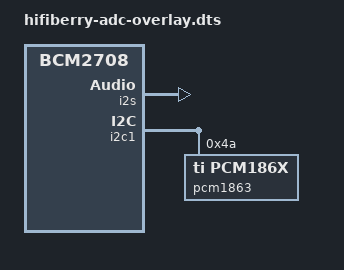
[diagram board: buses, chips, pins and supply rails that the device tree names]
// Definitions for HiFiBerry Digi
/dts-v1/;
/plugin/;

/ {
	compatible = "brcm,bcm2708";

	fragment@0 {
		target = <&sound>;
		__overlay__ {
			compatible = "hifiberry,hifiberry-adc";
			i2s-controller = <&i2s>;
			status = "okay";
		};
	};

	fragment@1 {
		target = <&i2s>;
		__overlay__ {
			status = "okay";
		};
	};

	fragment@2 {
		target = <&i2c1>;
		__overlay__ {
			#address-cells = <1>;
			#size-cells = <0>;
			status = "okay";

			pcm1863@4a {
				#sound-dai-cells = <0>;
				compatible = "ti,pcm186x";
				reg = <0x4a>;
				status = "okay";
			};
		};
	};
};
